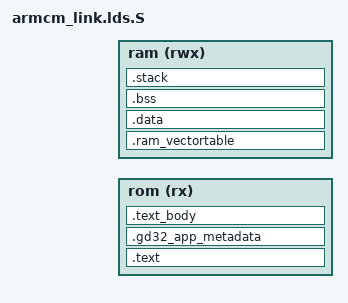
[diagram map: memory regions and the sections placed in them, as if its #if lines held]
// Generic ARM Cortex-M linker script
//
// Copyright (C) 2019  Kevin O'Connor <kevin@koconnor.net>
//
// This file may be distributed under the terms of the GNU GPLv3 license.

#include "autoconf.h" // CONFIG_FLASH_APPLICATION_ADDRESS

OUTPUT_FORMAT("elf32-littlearm", "elf32-littlearm", "elf32-littlearm")
OUTPUT_ARCH(arm)

MEMORY
{
  rom (rx) : ORIGIN = CONFIG_FLASH_APPLICATION_ADDRESS , LENGTH = CONFIG_FLASH_SIZE
  ram (rwx) : ORIGIN = CONFIG_RAM_START , LENGTH = CONFIG_RAM_SIZE
}

SECTIONS
{
    .text : {
        . = ALIGN(4);
        _text_vectortable_start = .;
        KEEP(*(.vector_table))
        _text_vectortable_end = .;
#if !CONFIG_MACH_GD32
        *(.text .text.*)
        *(.rodata .rodata*)
#endif
    } > rom

#if CONFIG_MACH_GD32
    /* The factory GD32 bootloader reads version/CRC/length at fixed
     * application offsets.  host_crc16 writes bytes 0x20c..0x211 after
     * objcopy, so executable code must never be linked across them. */
    ASSERT(_text_vectortable_end <= ORIGIN(rom) + 0x200,
           "GD32 vector table overlaps application metadata")
    .gd32_app_metadata ORIGIN(rom) + 0x200 : {
        _gd32_app_metadata_start = .;
        KEEP(*(.gd32_app_metadata))
        _gd32_app_metadata_end = .;
    } > rom
    ASSERT(SIZEOF(.gd32_app_metadata) == 0x12,
           "GD32 application metadata must be exactly 18 bytes")
    .text_body : {
        *(.text .text.*)
        *(.rodata .rodata*)
    } > rom
#endif

    . = ALIGN(4);
    _data_flash = .;

#if CONFIG_ARMCM_RAM_VECTORTABLE
    .ram_vectortable (NOLOAD) : {
        _ram_vectortable_start = .;
        . = . + ( _text_vectortable_end - _text_vectortable_start ) ;
        _ram_vectortable_end = .;
    } > ram
#endif

    .data : AT (_data_flash)
    {
        . = ALIGN(4);
        _data_start = .;
        *(.ramfunc .ramfunc.*);
        *(.data .data.*);
        . = ALIGN(4);
        _data_end = .;
    } > ram

    .bss (NOLOAD) :
    {
        . = ALIGN(4);
        _bss_start = .;
        *(.bss .bss.*)
        *(COMMON)
        . = ALIGN(4);
        _bss_end = .;
    } > ram

    _stack_start = CONFIG_RAM_START + CONFIG_RAM_SIZE - CONFIG_STACK_SIZE ;
    .stack _stack_start (NOLOAD) :
    {
        . = . + CONFIG_STACK_SIZE;
        _stack_end = .;
    } > ram

    /DISCARD/ : {
        // The .init/.fini sections are used by __libc_init_array(), but
        // that isn't needed so no need to include them in the binary.
        *(.init)
        *(.fini)
        // Don't include exception tables
        *(.ARM.extab)
        *(.ARM.exidx)
    }
}
